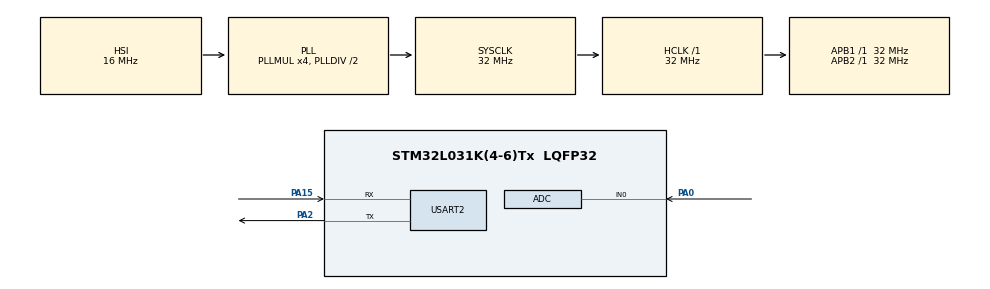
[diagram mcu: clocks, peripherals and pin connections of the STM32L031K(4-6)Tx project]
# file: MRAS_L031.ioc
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ADC.ClockPrescaler=ADC_CLOCK_SYNC_PCLK_DIV2
ADC.DMAContinuousRequests=ENABLE
ADC.ExternalTrigConv=ADC_EXTERNALTRIGCONV_T2_TRGO
ADC.Overrun=ADC_OVR_DATA_OVERWRITTEN
Dma.ADC.0.Direction=DMA_PERIPH_TO_MEMORY
Dma.ADC.0.Instance=DMA1_Channel1
Dma.ADC.0.MemDataAlignment=DMA_MDATAALIGN_HALFWORD
Dma.ADC.0.MemInc=DMA_MINC_ENABLE
Dma.ADC.0.Mode=DMA_NORMAL
Dma.ADC.0.PeriphDataAlignment=DMA_PDATAALIGN_HALFWORD
Dma.ADC.0.PeriphInc=DMA_PINC_DISABLE
Dma.ADC.0.Priority=DMA_PRIORITY_HIGH
Dma.Request0=ADC
Mcu.Family=STM32L0
Mcu.Name=STM32L031K(4-6)Tx
Mcu.Package=LQFP32
NVIC.DMA1_Channel1_IRQn=true\:0\:0\:false\:false\:true\:false\:true\:true
PA0-CK_IN.Mode=IN0
PA0-CK_IN.Signal=ADC_IN0
PA13.Mode=Serial_Wire
PA13.Signal=SYS_SWDIO
PA14.Mode=Serial_Wire
PA14.Signal=SYS_SWCLK
PA15.Mode=Asynchronous
PA15.Signal=USART2_RX
PA2.Mode=Asynchronous
PA2.Signal=USART2_TX
ProjectManager.HeapSize=0x200
ProjectManager.StackSize=0x400
ProjectManager.TargetToolchain=CMake
RCC.ADCFreq_Value=16000000
RCC.AHBFreq_Value=32000000
RCC.APB1Freq_Value=32000000
RCC.APB1TimFreq_Value=32000000
RCC.APB2Freq_Value=32000000
RCC.APB2TimFreq_Value=32000000
RCC.HCLKFreq_Value=32000000
RCC.HSE_VALUE=8000000
RCC.HSI16_VALUE=16000000
RCC.HSI_VALUE=16000000
RCC.LSE_VALUE=32768
RCC.MSI_VALUE=2097000
RCC.PLLMUL=RCC_PLLMUL_4
RCC.SYSCLKFreq_VALUE=32000000
RCC.SYSCLKSource=RCC_SYSCLKSOURCE_PLLCLK
RCC.VCOOutputFreq_Value=64000000
TIM2.Period=39
TIM2.TIM_MasterOutputTrigger=TIM_TRGO_UPDATE
USART2.VirtualMode-Asynchronous=VM_ASYNC
VP_TIM2_VS_ClockSourceINT.Mode=Internal
board=custom

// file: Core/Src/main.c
/* USER CODE BEGIN Header */
/**
  ******************************************************************************
  * @file           : main.c
  * @brief          : Main program body
  ******************************************************************************
  * @attention
  *
  * Copyright (c) 2026 STMicroelectronics.
  * All rights reserved.
  *
  * This software is licensed under terms that can be found in the LICENSE file
  * in the root directory of this software component.
  * If no LICENSE file comes with this software, it is provided AS-IS.
  *
  ******************************************************************************
  */
/* USER CODE END Header */
#include "main.h"

/* USER CODE BEGIN Includes */
#include <stdio.h>
#include <string.h>
/* USER CODE END Includes */

ADC_HandleTypeDef hadc;
DMA_HandleTypeDef hdma_adc;

TIM_HandleTypeDef htim2;

UART_HandleTypeDef huart2;

void SystemClock_Config(void);
static void MX_GPIO_Init(void);
static void MX_DMA_Init(void);
static void MX_ADC_Init(void);
static void MX_TIM2_Init(void);
static void MX_USART2_UART_Init(void);

/* USER CODE BEGIN 0 */
/* MRAS: finite DMA blocks, nominal 800 kS/s, external 100 kHz.
 * Short 64-sample Fourier windows limit sensitivity to HSI clock error.
 * No TX phase reference: amplitude only. Calibration is held in RAM. */
#define MRAS_N 64U
#define MRAS_BLOCKS 16U
static uint16_t adc_samples[MRAS_N] __attribute__((aligned(4)));
static volatile uint8_t adc_done;
static uint32_t refs[6];
static uint8_t valid[6];
static const char *const names[6]={"Air", "Aluminum", "Copper", "Steel", "Stainless steel", "Brass"};
static const int16_t cos8[8]={256,181,0,-181,-256,-181,0,181};
static const int16_t sin8[8]={0,181,256,181,0,-181,-256,-181};
static void send(const char *s){ HAL_UART_Transmit(&huart2,(uint8_t *)s,(uint16_t)strlen(s),200); }
static uint32_t root64(uint64_t x){
    uint64_t r=0, b=(uint64_t)1<<62;
    while(b>x) b>>=2;
    while(b){if(x>=r+b){x-=r+b;r=(r>>1)+b;}else r>>=1;b>>=2;}
    return (uint32_t)r;
}
void HAL_ADC_ConvCpltCallback(ADC_HandleTypeDef *h){
    if(h->Instance==ADC1){HAL_TIM_Base_Stop(&htim2);adc_done=1;}
}
static int measure(uint32_t *peak, uint32_t *dc){
    uint32_t total=0, bias=0;
    for(unsigned b=0;b<MRAS_BLOCKS;b++){
        adc_done=0;
        __HAL_TIM_SET_COUNTER(&htim2,0);
        if(HAL_ADC_Start_DMA(&hadc,(uint32_t *)adc_samples,MRAS_N)!=HAL_OK){HAL_ADC_Stop_DMA(&hadc);return 0;}
        if(HAL_TIM_Base_Start(&htim2)!=HAL_OK){HAL_ADC_Stop_DMA(&hadc);return 0;}
        uint32_t start=HAL_GetTick();
        while(!adc_done && HAL_GetTick()-start<30U){}
        HAL_TIM_Base_Stop(&htim2);
        if(HAL_ADC_Stop_DMA(&hadc)!=HAL_OK || !adc_done) return 0;
        int32_t i=0,q=0;
        for(unsigned k=0;k<MRAS_N;k++){
            uint16_t v=adc_samples[k];
            if(v<=5 || v>=4090) return -1;
            bias+=v;
            i+=(int32_t)v*cos8[k&7U];q+=(int32_t)v*sin8[k&7U];
        }
        uint64_t power=(uint64_t)((int64_t)i*i)+(uint64_t)((int64_t)q*q);
        total+=(2U*root64(power)+MRAS_N*128U)/(MRAS_N*256U);
    }
    *peak=(total+MRAS_BLOCKS/2U)/MRAS_BLOCKS;
    *dc=bias/(MRAS_N*MRAS_BLOCKS);
    return 1;
}
static void mras_task(void){
    uint8_t cmd; uint32_t a,dc; char msg[150];
    if(HAL_UART_Receive(&huart2,&cmd,1,100)!=HAL_OK)return;
    if(cmd=='?' || cmd=='h'){send("0=air 1=Al 2=Cu 3=steel 4=stainless 5=brass m=measure r=classify\r\n");return;}
    if(!((cmd>='0' && cmd<='5') || cmd=='m' || cmd=='r'))return;
    int ok=measure(&a,&dc);
    if(ok==0){send("ADC/DMA acquisition error\r\n");return;}
    if(ok<0){send("ADC near rail: check bias/gain/input\r\n");return;}
    snprintf(msg,sizeof msg,"Peak=%lu counts (~%lu mV assuming 3.3V), DC=%lu counts\r\n",(unsigned long)a,(unsigned long)((a*3300U+2048U)/4096U),(unsigned long)dc);send(msg);
    if(cmd=='m')return;
    if(cmd>='0' && cmd<='5'){
        unsigned j=cmd-'0';refs[j]=a;valid[j]=1;
        snprintf(msg,sizeof msg,"Calibrated %s\r\n",names[j]);send(msg);return;
    }
    for(unsigned j=0;j<6;j++)if(!valid[j]){send("Calibrate all 6 references first\r\n");return;}
    unsigned best=0;uint32_t d=UINT32_MAX,second=UINT32_MAX;
    for(unsigned j=0;j<6;j++){
        uint32_t e=a>refs[j]?a-refs[j]:refs[j]-a;
        if(e<d){second=d;d=e;best=j;}else if(e<second)second=e;
    }
    /* Initial thresholds only; tune against repeated experimental measurements. */
    const char *label=(d>20U || second-d<10U)?"Unknown / ambiguous":names[best];
    snprintf(msg,sizeof msg,"Detected: %s | distance=%lu counts\r\n",label,(unsigned long)d);send(msg);
}

/* USER CODE END 0 */

int main(void)
{

  /* MCU Configuration--------------------------------------------------------*/

  /* Reset of all peripherals, Initializes the Flash interface and the Systick. */
  HAL_Init();

  /* Configure the system clock */
  SystemClock_Config();

  /* Initialize all configured peripherals */
  MX_GPIO_Init();
  MX_DMA_Init();
  MX_ADC_Init();
  MX_TIM2_Init();
  MX_USART2_UART_Init();

/* USER CODE BEGIN 2 */
  if(HAL_ADCEx_Calibration_Start(&hadc, ADC_SINGLE_ENDED)!=HAL_OK){
    send("ADC calibration failed\r\n");
    Error_Handler();
  }
  send("MRAS L031 ready. 0=air 1=Al 2=Cu 3=steel 4=stainless 5=brass m=measure r=classify\r\n");
/* USER CODE END 2 */

  /* Infinite loop */

while (1)
{

    /* USER CODE BEGIN 3 */
    mras_task();
  }
/* USER CODE END 3 */
}

void SystemClock_Config(void)
{
  RCC_OscInitTypeDef RCC_OscInitStruct = {0};
  RCC_ClkInitTypeDef RCC_ClkInitStruct = {0};
  RCC_PeriphCLKInitTypeDef PeriphClkInit = {0};

  /** Configure the main internal regulator output voltage
  */
  __HAL_PWR_VOLTAGESCALING_CONFIG(PWR_REGULATOR_VOLTAGE_SCALE1);

  /** Initializes the RCC Oscillators according to the specified parameters
  * in the RCC_OscInitTypeDef structure.
  */
  RCC_OscInitStruct.OscillatorType = RCC_OSCILLATORTYPE_HSI;
  RCC_OscInitStruct.HSIState = RCC_HSI_ON;
  RCC_OscInitStruct.HSICalibrationValue = RCC_HSICALIBRATION_DEFAULT;
  RCC_OscInitStruct.PLL.PLLState = RCC_PLL_ON;
  RCC_OscInitStruct.PLL.PLLSource = RCC_PLLSOURCE_HSI;
  RCC_OscInitStruct.PLL.PLLMUL = RCC_PLLMUL_4;
  RCC_OscInitStruct.PLL.PLLDIV = RCC_PLLDIV_2;
  if (HAL_RCC_OscConfig(&RCC_OscInitStruct) != HAL_OK)
  {
    Error_Handler();
  }

  /** Initializes the CPU, AHB and APB buses clocks
  */
  RCC_ClkInitStruct.ClockType = RCC_CLOCKTYPE_HCLK|RCC_CLOCKTYPE_SYSCLK
                              |RCC_CLOCKTYPE_PCLK1|RCC_CLOCKTYPE_PCLK2;
  RCC_ClkInitStruct.SYSCLKSource = RCC_SYSCLKSOURCE_PLLCLK;
  RCC_ClkInitStruct.AHBCLKDivider = RCC_SYSCLK_DIV1;
  RCC_ClkInitStruct.APB1CLKDivider = RCC_HCLK_DIV1;
  RCC_ClkInitStruct.APB2CLKDivider = RCC_HCLK_DIV1;

  if (HAL_RCC_ClockConfig(&RCC_ClkInitStruct, FLASH_LATENCY_1) != HAL_OK)
  {
    Error_Handler();
  }
  PeriphClkInit.PeriphClockSelection = RCC_PERIPHCLK_USART2;
  PeriphClkInit.Usart2ClockSelection = RCC_USART2CLKSOURCE_PCLK1;
  if (HAL_RCCEx_PeriphCLKConfig(&PeriphClkInit) != HAL_OK)
  {
    Error_Handler();
  }
}

static void MX_ADC_Init(void)
{

  ADC_ChannelConfTypeDef sConfig = {0};

  /** Configure the global features of the ADC (Clock, Resolution, Data Alignment and number of conversion)
  */
  hadc.Instance = ADC1;
  hadc.Init.OversamplingMode = DISABLE;
  hadc.Init.ClockPrescaler = ADC_CLOCK_SYNC_PCLK_DIV2;
  hadc.Init.Resolution = ADC_RESOLUTION_12B;
  hadc.Init.SamplingTime = ADC_SAMPLETIME_1CYCLE_5;
  hadc.Init.ScanConvMode = ADC_SCAN_DIRECTION_FORWARD;
  hadc.Init.DataAlign = ADC_DATAALIGN_RIGHT;
  hadc.Init.ContinuousConvMode = DISABLE;
  hadc.Init.DiscontinuousConvMode = DISABLE;
  hadc.Init.ExternalTrigConvEdge = ADC_EXTERNALTRIGCONVEDGE_RISING;
  hadc.Init.ExternalTrigConv = ADC_EXTERNALTRIGCONV_T2_TRGO;
  hadc.Init.DMAContinuousRequests = ENABLE;
  hadc.Init.EOCSelection = ADC_EOC_SINGLE_CONV;
  hadc.Init.Overrun = ADC_OVR_DATA_OVERWRITTEN;
  hadc.Init.LowPowerAutoWait = DISABLE;
  hadc.Init.LowPowerFrequencyMode = DISABLE;
  hadc.Init.LowPowerAutoPowerOff = DISABLE;
  if (HAL_ADC_Init(&hadc) != HAL_OK)
  {
    Error_Handler();
  }

  /** Configure for the selected ADC regular channel to be converted.
  */
  sConfig.Channel = ADC_CHANNEL_0;
  sConfig.Rank = ADC_RANK_CHANNEL_NUMBER;
  if (HAL_ADC_ConfigChannel(&hadc, &sConfig) != HAL_OK)
  {
    Error_Handler();
  }

}

static void MX_TIM2_Init(void)
{

  TIM_ClockConfigTypeDef sClockSourceConfig = {0};
  TIM_MasterConfigTypeDef sMasterConfig = {0};

  htim2.Instance = TIM2;
  htim2.Init.Prescaler = 0;
  htim2.Init.CounterMode = TIM_COUNTERMODE_UP;
  htim2.Init.Period = 39;
  htim2.Init.ClockDivision = TIM_CLOCKDIVISION_DIV1;
  htim2.Init.AutoReloadPreload = TIM_AUTORELOAD_PRELOAD_DISABLE;
  if (HAL_TIM_Base_Init(&htim2) != HAL_OK)
  {
    Error_Handler();
  }
  sClockSourceConfig.ClockSource = TIM_CLOCKSOURCE_INTERNAL;
  if (HAL_TIM_ConfigClockSource(&htim2, &sClockSourceConfig) != HAL_OK)
  {
    Error_Handler();
  }
  sMasterConfig.MasterOutputTrigger = TIM_TRGO_UPDATE;
  sMasterConfig.MasterSlaveMode = TIM_MASTERSLAVEMODE_DISABLE;
  if (HAL_TIMEx_MasterConfigSynchronization(&htim2, &sMasterConfig) != HAL_OK)
  {
    Error_Handler();
  }

}

static void MX_USART2_UART_Init(void)
{

  huart2.Instance = USART2;
  huart2.Init.BaudRate = 115200;
  huart2.Init.WordLength = UART_WORDLENGTH_8B;
  huart2.Init.StopBits = UART_STOPBITS_1;
  huart2.Init.Parity = UART_PARITY_NONE;
  huart2.Init.Mode = UART_MODE_TX_RX;
  huart2.Init.HwFlowCtl = UART_HWCONTROL_NONE;
  huart2.Init.OverSampling = UART_OVERSAMPLING_16;
  huart2.Init.OneBitSampling = UART_ONE_BIT_SAMPLE_DISABLE;
  huart2.AdvancedInit.AdvFeatureInit = UART_ADVFEATURE_NO_INIT;
  if (HAL_UART_Init(&huart2) != HAL_OK)
  {
    Error_Handler();
  }

}

static void MX_DMA_Init(void)
{

  /* DMA controller clock enable */
  __HAL_RCC_DMA1_CLK_ENABLE();

  /* DMA interrupt init */
  /* DMA1_Channel1_IRQn interrupt configuration */
  HAL_NVIC_SetPriority(DMA1_Channel1_IRQn, 0, 0);
  HAL_NVIC_EnableIRQ(DMA1_Channel1_IRQn);

}

static void MX_GPIO_Init(void)
{

  /* GPIO Ports Clock Enable */
  __HAL_RCC_GPIOA_CLK_ENABLE();

}

void Error_Handler(void)
{
  __disable_irq();
  while (1)
  {
  }
}
